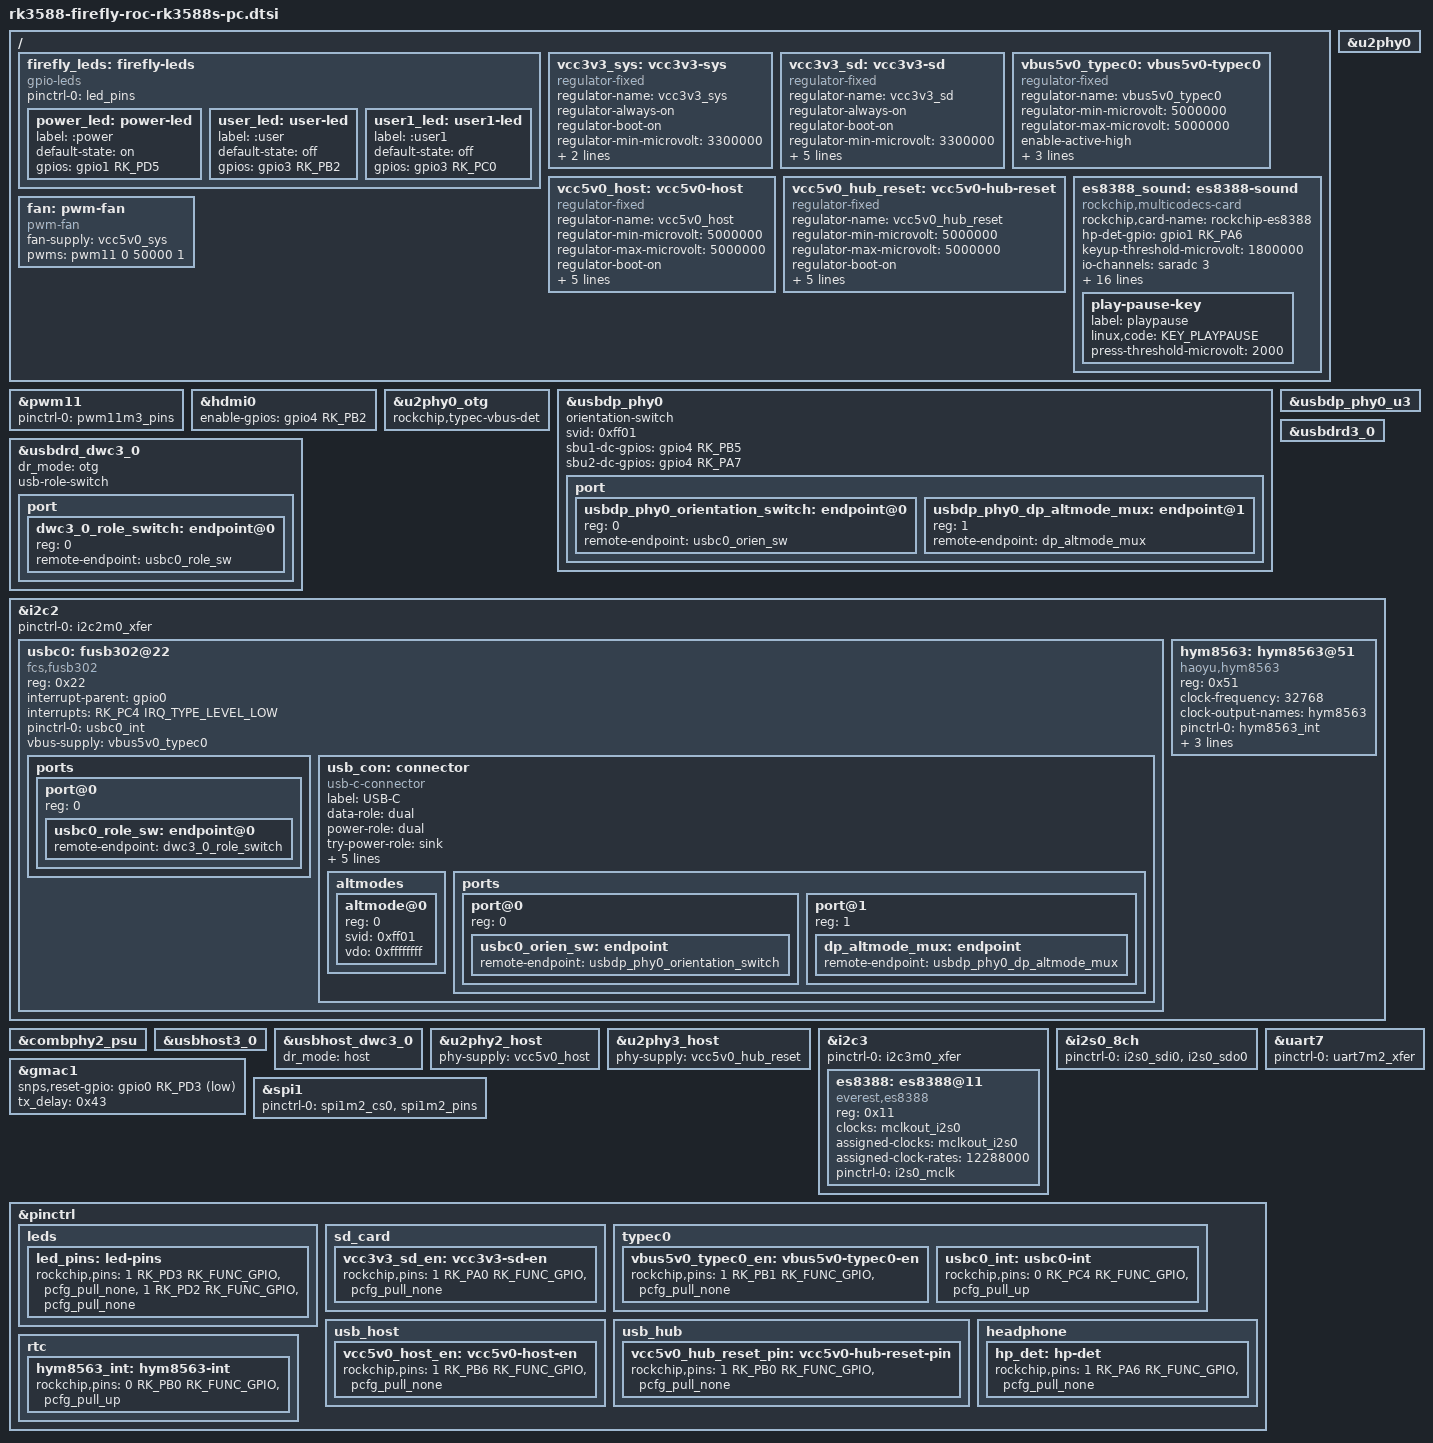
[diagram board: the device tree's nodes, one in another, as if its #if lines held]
// SPDX-License-Identifier: (GPL-2.0+ OR MIT)
/*
 * Copyright (c) 2022 Rockchip Electronics Co., Ltd.
 *
 */
#include <dt-bindings/leds/common.h>
#include "rk3588-firefly-common.dtsi"

/ {
#ifdef FF_LEDS
	firefly_leds: firefly-leds {
		status = "okay";
		compatible = "gpio-leds";
		pinctrl-names = "default";
		pinctrl-0 = <&led_pins>;

		power_led: power-led {
			label = ":power"; // blue
			default-state = "on";
			gpios = <&gpio1 RK_PD5 GPIO_ACTIVE_HIGH>;
		};

		user_led: user-led {
			label = ":user"; // red
			default-state = "off";
			gpios = <&gpio3 RK_PB2 GPIO_ACTIVE_HIGH>;
		};

		user1_led: user1-led {
			label = ":user1"; // green
			default-state = "off";
			gpios = <&gpio3 RK_PC0 GPIO_ACTIVE_HIGH>;
		};
	};
#endif

	vcc3v3_sys: vcc3v3-sys {
		compatible = "regulator-fixed";
		regulator-name = "vcc3v3_sys";
		regulator-always-on;
		regulator-boot-on;
		regulator-min-microvolt = <3300000>;
		regulator-max-microvolt = <3300000>;
		vin-supply = <&vcc12v_dcin>;
	};

#ifdef FF_SDCARD
	vcc3v3_sd: vcc3v3-sd {
		compatible = "regulator-fixed";
		regulator-name = "vcc3v3_sd";
		regulator-always-on;
		regulator-boot-on;
		regulator-min-microvolt = <3300000>;
		regulator-max-microvolt = <3300000>;
		enable-active-low;
		gpio = <&gpio1 RK_PA0 GPIO_ACTIVE_LOW>;
		pinctrl-names = "default";
		pinctrl-0 = <&vcc3v3_sd_en>;
		vin-supply = <&vcc_3v3_s3>;
	};
#endif

#ifdef FF_TYPEC0
	vbus5v0_typec0: vbus5v0-typec0 {
		compatible = "regulator-fixed";
		regulator-name = "vbus5v0_typec0";
		regulator-min-microvolt = <5000000>;
		regulator-max-microvolt = <5000000>;
		enable-active-high;
		gpio = <&gpio1 RK_PB1 GPIO_ACTIVE_HIGH>;
		pinctrl-names = "default";
		pinctrl-0 = <&vbus5v0_typec0_en>;
		vin-supply = <&vcc5v0_sys>;
	};
#endif

#if defined(FF_USB30) || defined(FF_USB20_HOST0)
	vcc5v0_host: vcc5v0-host {
		compatible = "regulator-fixed";
		regulator-name = "vcc5v0_host";
		regulator-min-microvolt = <5000000>;
		regulator-max-microvolt = <5000000>;
		regulator-boot-on;
		regulator-always-on;
		enable-active-high;
		gpio = <&gpio1 RK_PB6 GPIO_ACTIVE_HIGH>;
		pinctrl-names = "default";
		pinctrl-0 = <&vcc5v0_host_en>;
		vin-supply = <&vcc5v0_usb>;
	};
#endif

#ifdef FF_USB20_HOST1
	vcc5v0_hub_reset: vcc5v0-hub-reset {
		compatible = "regulator-fixed";
		regulator-name = "vcc5v0_hub_reset";
		regulator-min-microvolt = <5000000>;
		regulator-max-microvolt = <5000000>;
		regulator-boot-on;
		regulator-always-on;
		enable-active-high;
		gpio = <&gpio1 RK_PB0 GPIO_ACTIVE_HIGH>;
		pinctrl-names = "default";
		pinctrl-0 = <&vcc5v0_hub_reset_pin>;
		vin-supply = <&vcc5v0_usb>;
	};
#endif

#ifdef FF_CODEC_ES8388
	es8388_sound: es8388-sound {
		status = "okay";
		compatible = "rockchip,multicodecs-card";
		rockchip,card-name = "rockchip-es8388";
		hp-det-gpio = <&gpio1 RK_PA6 GPIO_ACTIVE_HIGH>;
		keyup-threshold-microvolt = <1800000>;
		io-channels = <&saradc 3>;
		io-channel-names = "adc-detect";
		poll-interval = <100>;
		hp-con-gpio = <&gpio1 RK_PA4 GPIO_ACTIVE_HIGH>;
		rockchip,pre-power-on-delay-ms = <30>;
		rockchip,post-power-down-delay-ms = <40>;
		rockchip,format = "i2s";
		rockchip,mclk-fs = <256>;
		rockchip,cpu = <&i2s0_8ch>;
		rockchip,codec = <&es8388>;
		rockchip,audio-routing =
			"Speaker", "LOUT1",
			"Speaker", "ROUT1",
			"Headphone", "LOUT2",
			"Headphone", "ROUT2",
			"Headphone", "Headphone Power",
			"Headphone", "Headphone Power",
			"Speaker", "Speaker Power",
			"Speaker", "Speaker Power",
			"LINPUT1", "Headset Mic",
			"RINPUT1", "Headset Mic",
			"LINPUT2", "Main Mic",
			"RINPUT2", "Main Mic";
		pinctrl-names = "default";
		pinctrl-0 = <&hp_det>;
		play-pause-key {
			label = "playpause";
			linux,code = <KEY_PLAYPAUSE>;
			press-threshold-microvolt = <2000>;
		};
	};
#endif

#ifdef FF_FAN
	fan: pwm-fan {
		compatible = "pwm-fan";
		#cooling-cells = <2>;
		fan-supply = <&vcc5v0_sys>;
		pwms = <&pwm11 0 50000 1>;
	};
#endif
};

#ifdef FF_FAN
&pwm11 {
	status = "okay";
	pinctrl-names = "active";
	pinctrl-0 = <&pwm11m3_pins>;
};
#endif

#ifdef FF_HDMI0
&hdmi0 {
	enable-gpios = <&gpio4 RK_PB2 GPIO_ACTIVE_HIGH>;
	status = "okay";
};
#endif

#ifdef FF_TYPEC0
&u2phy0 {
	status = "okay";
};

&u2phy0_otg {
	status = "okay";
	rockchip,typec-vbus-det;
};

&usbdp_phy0 {
	status = "okay";
	orientation-switch;
	svid = <0xff01>;
	sbu1-dc-gpios = <&gpio4 RK_PB5 GPIO_ACTIVE_HIGH>;
	sbu2-dc-gpios = <&gpio4 RK_PA7 GPIO_ACTIVE_HIGH>;

	port {
		#address-cells = <1>;
		#size-cells = <0>;
		usbdp_phy0_orientation_switch: endpoint@0 {
			reg = <0>;
			remote-endpoint = <&usbc0_orien_sw>;
		};

		usbdp_phy0_dp_altmode_mux: endpoint@1 {
			reg = <1>;
			remote-endpoint = <&dp_altmode_mux>;
		};
	};
};

&usbdp_phy0_u3 {
	status = "okay";
};

&usbdrd3_0 {
	status = "okay";
};

&usbdrd_dwc3_0 {
	status = "okay";
	dr_mode = "otg";
	usb-role-switch;
	port {
		#address-cells = <1>;
		#size-cells = <0>;
		dwc3_0_role_switch: endpoint@0 {
			reg = <0>;
			remote-endpoint = <&usbc0_role_sw>;
		};
	};
};

&i2c2 {
	status = "okay";
	pinctrl-names = "default";
	pinctrl-0 = <&i2c2m0_xfer>;

	usbc0: fusb302@22 {
		compatible = "fcs,fusb302";
		reg = <0x22>;
		interrupt-parent = <&gpio0>;
		interrupts = <RK_PC4 IRQ_TYPE_LEVEL_LOW>;
		pinctrl-names = "default";
		pinctrl-0 = <&usbc0_int>;
		vbus-supply = <&vbus5v0_typec0>;
		status = "okay";

		ports {
			#address-cells = <1>;
			#size-cells = <0>;

			port@0 {
				reg = <0>;
				usbc0_role_sw: endpoint@0 {
					remote-endpoint = <&dwc3_0_role_switch>;
				};
			};
		};

		usb_con: connector {
			compatible = "usb-c-connector";
			label = "USB-C";
			data-role = "dual";
			power-role = "dual";
			try-power-role = "sink";
			op-sink-microwatt = <1000000>;
			sink-pdos =
				<PDO_FIXED(5000, 1000, PDO_FIXED_USB_COMM)>;
			source-pdos =
				<PDO_FIXED(5000, 3000, PDO_FIXED_USB_COMM)>;

			altmodes {
				#address-cells = <1>;
				#size-cells = <0>;

				altmode@0 {
					reg = <0>;
					svid = <0xff01>;
					vdo = <0xffffffff>;
				};
			};

			ports {
				#address-cells = <1>;
				#size-cells = <0>;

				port@0 {
					reg = <0>;
					usbc0_orien_sw: endpoint {
						remote-endpoint = <&usbdp_phy0_orientation_switch>;
					};
				};

				port@1 {
					reg = <1>;
					dp_altmode_mux: endpoint {
						remote-endpoint = <&usbdp_phy0_dp_altmode_mux>;
					};
				};
			};
		};
	};
};
#endif

#ifdef FF_USB30 // Type-C1 to Type-A
&combphy2_psu {
	status = "okay";
};

&usbhost3_0 {
	status = "okay";
};

&usbhost_dwc3_0 {
	status = "okay";
	dr_mode = "host";
};
#endif

#ifdef FF_USB20_HOST0
&u2phy2_host {
        status = "okay";
	phy-supply = <&vcc5v0_host>;
};
#endif

#ifdef FF_USB20_HOST1
&u2phy3_host {
        status = "okay";
	phy-supply = <&vcc5v0_hub_reset>;
};
#endif

#ifdef FF_CODEC_ES8388
&i2c3 {
	status = "okay";
	pinctrl-names = "default";
	pinctrl-0 = <&i2c3m0_xfer>;

	es8388: es8388@11 {
		status = "okay";
		#sound-dai-cells = <0>;
		compatible = "everest,es8388", "everest,es8323";
		reg = <0x11>;
		clocks = <&mclkout_i2s0>;
		clock-names = "mclk";
		assigned-clocks = <&mclkout_i2s0>;
		assigned-clock-rates = <12288000>;
		pinctrl-names = "default";
		pinctrl-0 = <&i2s0_mclk>;
	};
};

&i2s0_8ch {
	status = "okay";
	pinctrl-0 = <&i2s0_sdi0
		     &i2s0_sdo0>;
};
#endif

#ifdef FF_GMAC1
&gmac1 {
	status = "okay";
	snps,reset-gpio = <&gpio0 RK_PD3 GPIO_ACTIVE_LOW>;
	tx_delay = <0x43>;
};
#endif

#ifdef FF_RTC
&i2c2 {
	status = "okay";
	pinctrl-names = "default";
	pinctrl-0 = <&i2c2m0_xfer>;

	hym8563: hym8563@51 {
		status = "okay";
		compatible = "haoyu,hym8563";
		reg = <0x51>;
		#clock-cells = <0>;
		clock-frequency = <32768>;
		clock-output-names = "hym8563";
		pinctrl-names = "default";
		pinctrl-0 = <&hym8563_int>;
		interrupt-parent = <&gpio0>;
		interrupts = <RK_PB0 IRQ_TYPE_LEVEL_LOW>;
		wakeup-source;
	};
};
#endif

#ifdef FF_SPI1
&spi1 {
	status = "okay";
	pinctrl-names = "default";
	pinctrl-0 = <&spi1m2_cs0 &spi1m2_pins>;
};
#endif

#ifdef FF_UART7
&uart7 {
	status = "okay";
	pinctrl-names = "default";
	pinctrl-0 = <&uart7m2_xfer>;
};
#endif

&pinctrl {
#ifdef FF_LEDS
	leds {
		led_pins: led-pins {
			rockchip,pins = <1 RK_PD3 RK_FUNC_GPIO &pcfg_pull_none>,
					<1 RK_PD2 RK_FUNC_GPIO &pcfg_pull_none>;
		};
	};
#endif

#ifdef FF_SDCARD
	sd_card {
		vcc3v3_sd_en: vcc3v3-sd-en {
			rockchip,pins = <1 RK_PA0 RK_FUNC_GPIO &pcfg_pull_none>;
		};
	};
#endif

#ifdef FF_TYPEC0
	typec0 {
		vbus5v0_typec0_en: vbus5v0-typec0-en {
			rockchip,pins = <1 RK_PB1 RK_FUNC_GPIO &pcfg_pull_none>;
		};

		usbc0_int: usbc0-int {
			rockchip,pins = <0 RK_PC4 RK_FUNC_GPIO &pcfg_pull_up>;
		};
	};
#endif

#if defined(FF_USB30) || defined(FF_USB20_HOST0)
	usb_host {
		vcc5v0_host_en: vcc5v0-host-en {
			rockchip,pins = <1 RK_PB6 RK_FUNC_GPIO &pcfg_pull_none>;
		};
	};
#endif

#ifdef FF_USB20_HOST1
	usb_hub {
		vcc5v0_hub_reset_pin: vcc5v0-hub-reset-pin {
			rockchip,pins = <1 RK_PB0 RK_FUNC_GPIO &pcfg_pull_none>;
		};
	};
#endif

#ifdef FF_CODEC_ES8388
	headphone {
		hp_det: hp-det {
			rockchip,pins = <1 RK_PA6 RK_FUNC_GPIO &pcfg_pull_none>;
		};
	};
#endif

#ifdef FF_RTC
	rtc {
		hym8563_int: hym8563-int {
			rockchip,pins = <0 RK_PB0 RK_FUNC_GPIO &pcfg_pull_up>;
		};
	};
#endif
};
